VERSION ""

NS_ :

BS_:

BU_: DBG

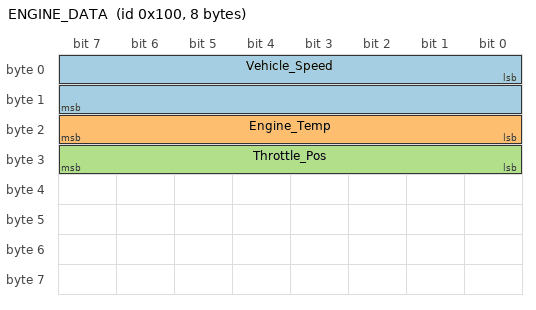
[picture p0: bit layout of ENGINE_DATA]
BO_ 256 ENGINE_DATA: 8 DBG
 SG_ Vehicle_Speed : 0|16@1+ (1,0) [0|16383.75] "rpm"  DBG
 SG_ Engine_Temp : 16|8@1+ (1,-40) [-40|215] "degC"  DBG
 SG_ Throttle_Pos : 24|8@1+ (0.4,0) [0|100] "%"  DBG
